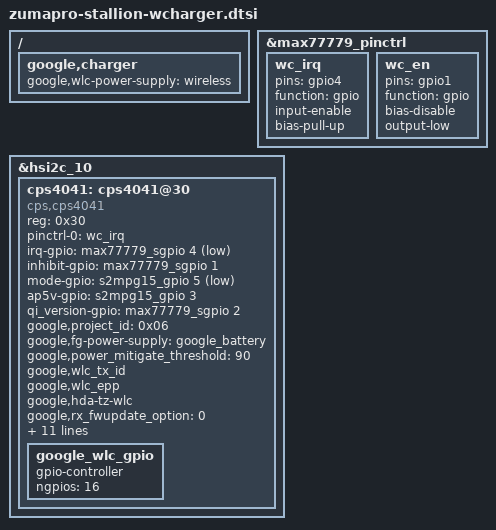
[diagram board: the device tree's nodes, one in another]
// SPDX-License-Identifier: GPL-2.0-only
/*
 * Wireless Charger device tree entries.
 *
 * Copyright 2024 Google LLC
 */

#include <arm64/exynos/exynos-pinctrl.h>
#include <dt-bindings/interrupt-controller/irq.h>

/ {
	fragment@wlc {
		target-path = "/";
		__overlay__ {
			google,charger {
				google,wlc-power-supply = "wireless";
			};
		};
	};
};

&max77779_pinctrl {
	/* QI_INT_ODL Wireless Charger Interrupt */
	wc_irq: wc_irq {
		pins = "gpio4";
		function = "gpio";
		input-enable;
		bias-pull-up;
	};

	/* QI_RX_COMM_EN_L Wireless Charger Enable */
	wc_en: wc_en {
		pins = "gpio1";
		function = "gpio";
		bias-disable;
		output-low;
	};

};

&hsi2c_10 {
	#address-cells = <1>;
	#size-cells = <0>;

	cps4041: cps4041@30 {
		compatible = "cps,cps4041";
		reg = <0x30>;
		status = "ok";

		pinctrl-names = "default";
		pinctrl-0 = <&wc_irq>;
		irq-gpio = <&max77779_sgpio 4 GPIO_ACTIVE_LOW>;
		inhibit-gpio = <&max77779_sgpio 1 GPIO_ACTIVE_HIGH>;
		mode-gpio = <&s2mpg15_gpio 5 GPIO_ACTIVE_LOW>;
		ap5v-gpio = <&s2mpg15_gpio 3 GPIO_ACTIVE_HIGH>;
		qi_version-gpio = <&max77779_sgpio 2 GPIO_ACTIVE_HIGH>;
		google,project_id = /bits/ 8 <0x06>;
		google,fg-power-supply = <&google_battery>;
		google,power_mitigate_threshold = <90>;
		google,wlc_tx_id;
		google,wlc_epp;
		google,hda-tz-wlc;
		google,rx_fwupdate_option = <0>;
		google,wlc-bootloader = "CPS4041_BL.bin";
		google,wlc-firmware = "CPS4041_A0_06.bin";
		bpp_mdis_pwr = <5000000 4884800 4769600 4654400 4539200 4424000 4308800 4193600 4078400
				3963200 3848000 3732800 3617600 3502400 3387200 3272000 3156800 3041600
				2926400 2811200 2696000 2580800 2465600 2350400 2235200 2120000>;
		epp_mdis_pwr = <10000000 9755200 9510400 9265600 9020800 8776000 8531200 8286400 8041600
				7796800 7552000 7307200 7062400 6817600 6572800 6328000 6083200 5838400
				5593600 5348800 5104000 4859200 4614400 4369600 4124800 3880000>;
		google,wcin_inlim_en-gpio = <&max77779_gpio 0 GPIO_ACTIVE_HIGH>;
		google,wlc_qispec = <0x2102>;
		google,iop_vout_mfg = /bits/ 16 <0x005D>;
		google,iop_vout_mv = <9000>;
		google,wlc_iop_bpp_vout_tolerance_mv = <500>;

		google_wlc_gpio: google_wlc_gpio {
			gpio-controller;
			#gpio-cells = <2>;
			ngpios = <16>;
		};
	};
};
